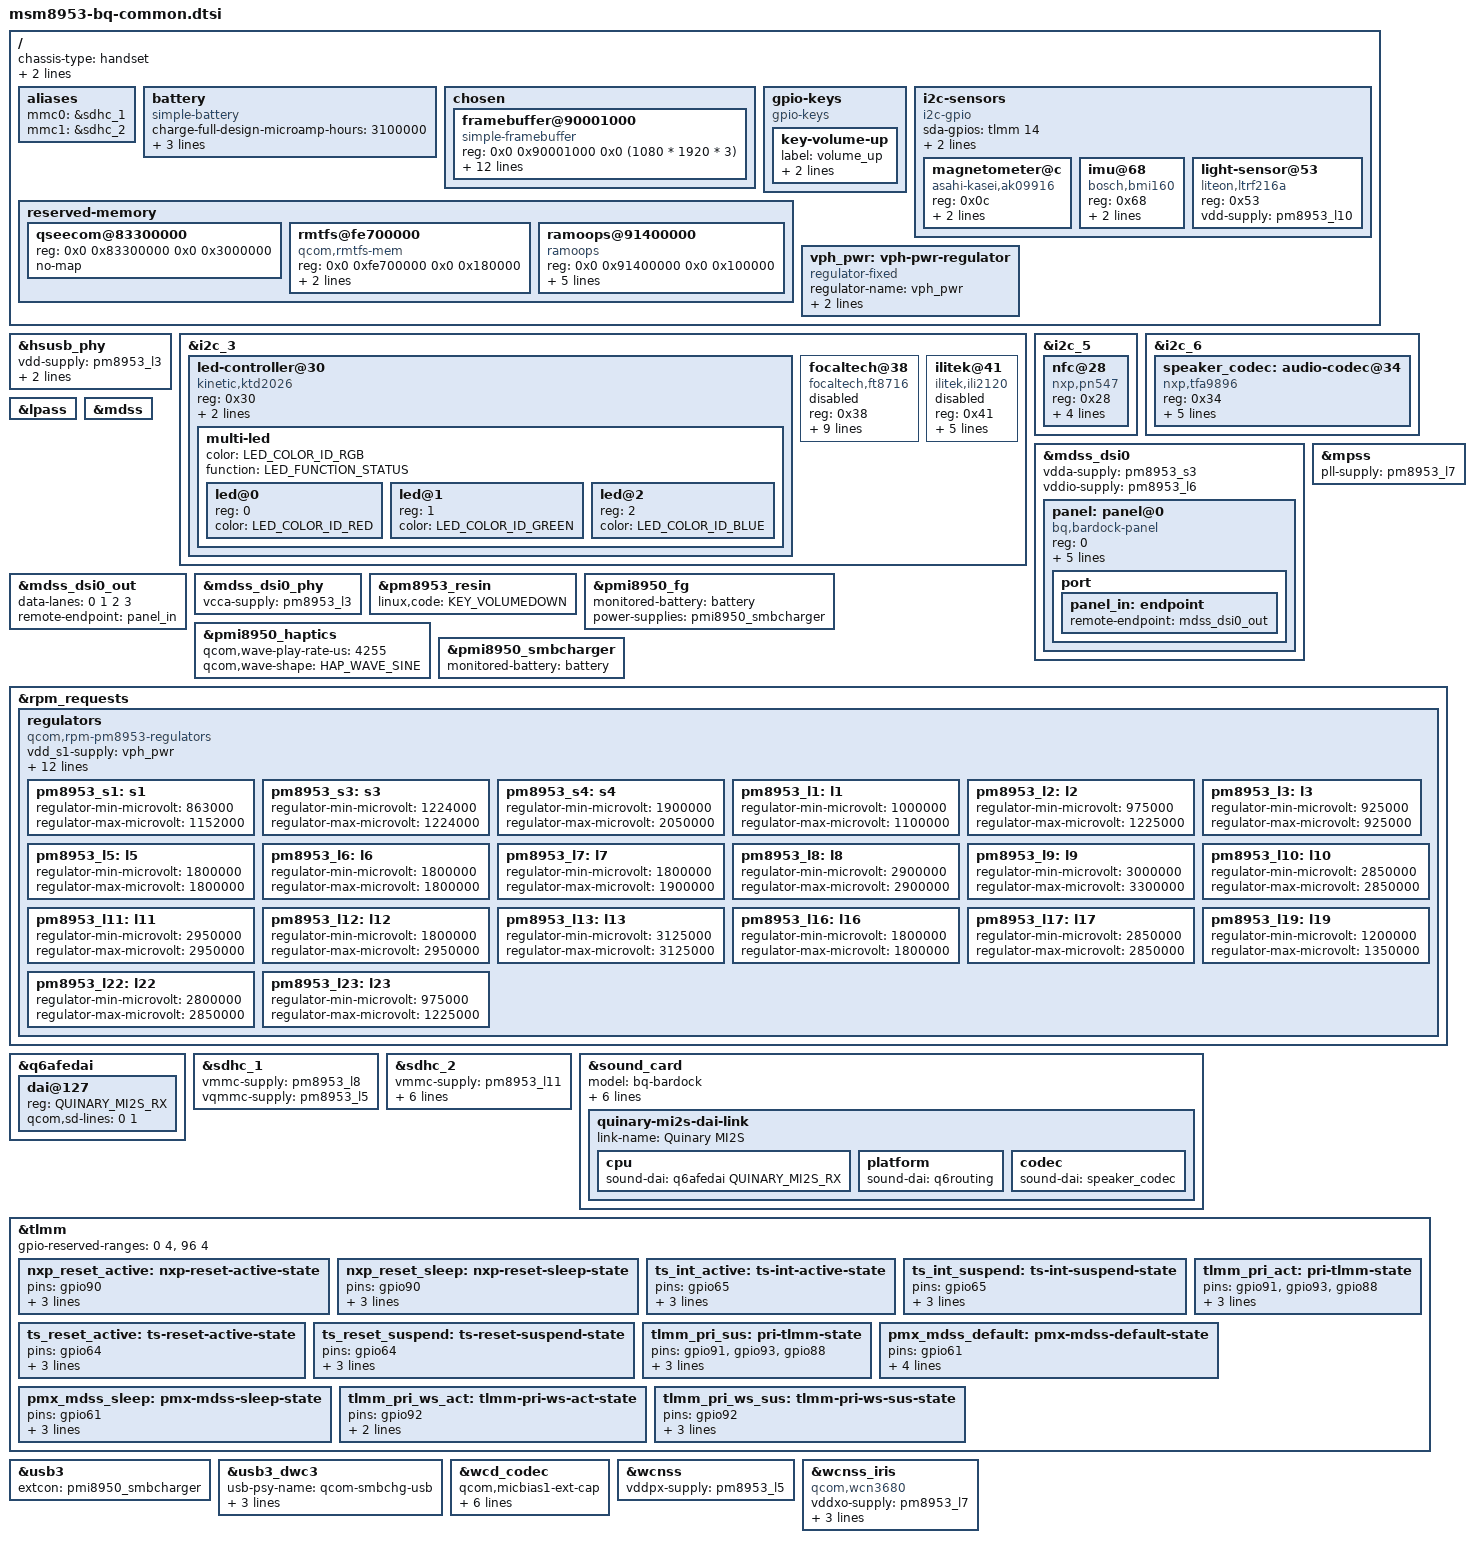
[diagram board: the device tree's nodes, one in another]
// SPDX-License-Identifier: BSD-3-Clause
/dts-v1/;

#include <dt-bindings/arm/qcom,ids.h>
#include <dt-bindings/leds/common.h>
#include "msm8953.dtsi"
#include "pm8953.dtsi"
#include "pmi8950.dtsi"

/delete-node/ &qseecom_mem;
/delete-node/ &rmtfs;

/ {
	chassis-type = "handset";
	qcom,msm-id = <QCOM_ID_MSM8953 0>;
	qcom,board-id = <QCOM_BOARD_ID(QRD, 32, 0) 0>;

	aliases {
		mmc0 = &sdhc_1;
		mmc1 = &sdhc_2;
	};

	battery: battery {
		compatible = "simple-battery";

		/* Either 3059mAh or 3133mAh depending on the battery used */
		charge-full-design-microamp-hours = <3100000>;
		constant-charge-current-max-microamp = <2100000>;
		voltage-min-design-microvolt = <3400000>;
		voltage-max-design-microvolt = <4400000>;
	};

	chosen {
		#address-cells = <2>;
		#size-cells = <2>;
		ranges;

		framebuffer@90001000 {
			compatible = "simple-framebuffer";
			reg = <0x0 0x90001000 0x0 (1080 * 1920 * 3)>;

			width = <1080>;
			height = <1920>;
			stride = <(1080 * 3)>;
			format = "r8g8b8";

			power-domains = <&gcc MDSS_GDSC>;

			clocks = <&gcc GCC_MDSS_AHB_CLK>,
				 <&gcc GCC_MDSS_AXI_CLK>,
				 <&gcc GCC_MDSS_VSYNC_CLK>,
				 <&gcc GCC_MDSS_MDP_CLK>,
				 <&gcc GCC_MDSS_BYTE0_CLK>,
				 <&gcc GCC_MDSS_PCLK0_CLK>,
				 <&gcc GCC_MDSS_ESC0_CLK>;
		};
	};

	gpio-keys {
		compatible = "gpio-keys";

		key-volume-up {
			label = "volume_up";
			linux,code = <KEY_VOLUMEUP>;
			gpios = <&tlmm 85 GPIO_ACTIVE_LOW>;
		};
	};

	/*
	 * We bitbang on &i2c_4 because BLSP is protected by TZ as sensors are
	 * normally proxied via ADSP firmware. GPIOs aren't protected.
	 */
	i2c-sensors {
		compatible = "i2c-gpio";
		sda-gpios = <&tlmm 14 (GPIO_ACTIVE_HIGH|GPIO_OPEN_DRAIN)>;
		scl-gpios = <&tlmm 15 (GPIO_ACTIVE_HIGH|GPIO_OPEN_DRAIN)>;
		i2c-gpio,delay-us = <2>; /* ~100 kHz */
		#address-cells = <1>;
		#size-cells = <0>;

		magnetometer@c {
			compatible = "asahi-kasei,ak09916";
			reg = <0x0c>;

			vdd-supply = <&pm8953_l10>;
			vid-supply = <&pm8953_l6>;
		};

		imu@68 {
			compatible = "bosch,bmi160";
			reg = <0x68>;

			vdd-supply = <&pm8953_l10>;
			vddio-supply = <&pm8953_l6>;
		};

		light-sensor@53 {
			/* it has ltr579 alps sensor */
			compatible = "liteon,ltrf216a";
			reg = <0x53>;
			vdd-supply = <&pm8953_l10>;
		};
	};

	reserved-memory {
		qseecom@83300000 {
			reg = <0x0 0x83300000 0x0 0x3000000>;
			no-map;
		};

		rmtfs@fe700000 {
			compatible = "qcom,rmtfs-mem";
			reg = <0x0 0xfe700000 0x0 0x180000>;
			no-map;

			qcom,client-id = <1>;
		};

		ramoops@91400000 {
			compatible = "ramoops";
			reg = <0x0 0x91400000 0x0 0x100000>;
			record-size = <0x10000>;
			console-size = <0x20000>;
			ftrace-size = <0x10000>;
			pmsg-size = <0x20000>;
			ecc-size = <0x10>;
		};
	};

	vph_pwr: vph-pwr-regulator {
		compatible = "regulator-fixed";
		regulator-name = "vph_pwr";
		regulator-always-on;
		regulator-boot-on;
	};
};

&hsusb_phy {
	vdd-supply = <&pm8953_l3>;
	vdda-pll-supply = <&pm8953_l7>;
	vdda-phy-dpdm-supply = <&pm8953_l13>;

	status = "okay";
};

&i2c_3 {
	status = "okay";

	led-controller@30 {
		compatible = "kinetic,ktd2026";
		reg = <0x30>;
		#address-cells = <1>;
		#size-cells = <0>;

		vin-supply = <&pm8953_l10>;
		vio-supply = <&pm8953_l6>;

		multi-led {
			color = <LED_COLOR_ID_RGB>;
			function = LED_FUNCTION_STATUS;

			#address-cells = <1>;
			#size-cells = <0>;

			led@0 {
				reg = <0>;
				color = <LED_COLOR_ID_RED>;
			};

			led@1 {
				reg = <1>;
				color = <LED_COLOR_ID_GREEN>;
			};

			led@2 {
				reg = <2>;
				color = <LED_COLOR_ID_BLUE>;
			};
		};
	};

	focaltech@38 {
		compatible = "focaltech,ft8716";
		reg = <0x38>;

		interrupt-parent = <&tlmm>;
		interrupts = <65 IRQ_TYPE_LEVEL_LOW>;

		pinctrl-names = "default", "sleep";
		pinctrl-0 = <&ts_reset_active &ts_int_active>;
		pinctrl-1 = <&ts_reset_suspend &ts_int_suspend>;

		reset-gpios = <&tlmm 64 GPIO_ACTIVE_LOW>;

		iovcc-supply = <&pm8953_l6>;
		vcc-supply = <&pm8953_l10>;

		touchscreen-size-x = <1080>;
		touchscreen-size-y = <1920>;

		status = "disabled";
	};

	ilitek@41 {
		compatible = "ilitek,ili2120";
		reg = <0x41>;

		interrupt-parent = <&tlmm>;
		interrupts = <65 IRQ_TYPE_LEVEL_LOW>;

		reset-gpios = <&tlmm 64 GPIO_ACTIVE_LOW>;

		touchscreen-size-x = <1080>;
		touchscreen-size-y = <1920>;

		status = "disabled";
	};
};

&i2c_5 {
	status = "okay";

	nfc@28 {
		compatible = "nxp,pn547", "nxp,nxp-nci-i2c";
		reg = <0x28>;

		interrupt-parent = <&tlmm>;
		interrupts = <17 IRQ_TYPE_EDGE_RISING>;

		enable-gpios = <&tlmm 16 GPIO_ACTIVE_HIGH>;
		firmware-gpios = <&tlmm 62 GPIO_ACTIVE_HIGH>;
	};
};

&i2c_6 {
	status = "okay";

	speaker_codec: audio-codec@34 {
		compatible = "nxp,tfa9896";
		reg = <0x34>;

		reset-gpio = <&tlmm 89 GPIO_ACTIVE_HIGH>;
		irq-gpio = <&tlmm 90 GPIO_ACTIVE_HIGH>;

		pinctrl-names = "default", "sleep";
		pinctrl-0 = <&nxp_reset_active>;
		pinctrl-1 = <&nxp_reset_sleep>;

		sound-name-prefix = "Speaker";
		#sound-dai-cells = <0>;
	};
};

&lpass {
	status = "okay";
};

&mdss {
	status = "okay";
};

&mdss_dsi0 {
	status = "okay";

	vdda-supply = <&pm8953_s3>;
	vddio-supply = <&pm8953_l6>;

	panel: panel@0 {
		compatible = "bq,bardock-panel";
		reg = <0>;

		pinctrl-names = "default", "sleep";
		pinctrl-0 = <&pmx_mdss_default &mdss_te_default>;
		pinctrl-1 = <&pmx_mdss_sleep &mdss_te_default>;

		reset-gpios = <&tlmm 61 GPIO_ACTIVE_LOW>;

		vsp-supply = <&lab_vreg>;
		vsn-supply = <&ibb_vreg>;

		port {
			panel_in: endpoint {
				remote-endpoint = <&mdss_dsi0_out>;
			};
		};
	};
};

&mdss_dsi0_out {
	data-lanes = <0 1 2 3>;
	remote-endpoint = <&panel_in>;
};

&mdss_dsi0_phy {
	vcca-supply = <&pm8953_l3>;

	status = "okay";
};

&mpss {
	pll-supply = <&pm8953_l7>;

	status = "okay";
};

&pm8953_resin {
	linux,code = <KEY_VOLUMEDOWN>;
	status = "okay";
};

&pmi8950_fg {
	monitored-battery = <&battery>;
	power-supplies = <&pmi8950_smbcharger>;
	status = "okay";
};

&pmi8950_haptics {
	qcom,wave-play-rate-us = <4255>;
	qcom,wave-shape = <HAP_WAVE_SINE>;
	status = "okay";
};

&pmi8950_smbcharger {
	monitored-battery = <&battery>;
	status = "okay";
};

&rpm_requests {
	regulators {
		compatible = "qcom,rpm-pm8953-regulators";

		vdd_s1-supply = <&vph_pwr>;
		vdd_s2-supply = <&vph_pwr>;
		vdd_s3-supply = <&vph_pwr>;
		vdd_s4-supply = <&vph_pwr>;
		vdd_s5-supply = <&vph_pwr>;
		vdd_s6-supply = <&vph_pwr>;
		vdd_s7-supply = <&vph_pwr>;
		vdd_l1-supply = <&pm8953_s3>;
		vdd_l2_l3-supply = <&pm8953_s3>;
		vdd_l4_l5_l6_l7_l16_l19-supply = <&pm8953_s4>;
		vdd_l8_l11_l12_l13_l14_l15-supply = <&vph_pwr>;
		vdd_l9_l10_l17_l18_l22-supply = <&vph_pwr>;
		vdd_l23-supply = <&pm8953_s3>;

		pm8953_s1: s1 {
			regulator-min-microvolt = <863000>;
			regulator-max-microvolt = <1152000>;
		};

		pm8953_s3: s3 {
			regulator-min-microvolt = <1224000>;
			regulator-max-microvolt = <1224000>;
		};

		pm8953_s4: s4 {
			regulator-min-microvolt = <1900000>;
			regulator-max-microvolt = <2050000>;
		};

		pm8953_l1: l1 {
			regulator-min-microvolt = <1000000>;
			regulator-max-microvolt = <1100000>;
		};

		pm8953_l2: l2 {
			regulator-min-microvolt = <975000>;
			regulator-max-microvolt = <1225000>;
		};

		pm8953_l3: l3 {
			regulator-min-microvolt = <925000>;
			regulator-max-microvolt = <925000>;
		};

		pm8953_l5: l5 {
			regulator-min-microvolt = <1800000>;
			regulator-max-microvolt = <1800000>;
		};

		pm8953_l6: l6 {
			regulator-min-microvolt = <1800000>;
			regulator-max-microvolt = <1800000>;
		};

		pm8953_l7: l7 {
			regulator-min-microvolt = <1800000>;
			regulator-max-microvolt = <1900000>;
		};

		pm8953_l8: l8 {
			regulator-min-microvolt = <2900000>;
			regulator-max-microvolt = <2900000>;
		};

		pm8953_l9: l9 {
			regulator-min-microvolt = <3000000>;
			regulator-max-microvolt = <3300000>;
		};

		pm8953_l10: l10 {
			regulator-min-microvolt = <2850000>;
			regulator-max-microvolt = <2850000>;
		};

		pm8953_l11: l11 {
			regulator-min-microvolt = <2950000>;
			regulator-max-microvolt = <2950000>;
		};

		pm8953_l12: l12 {
			regulator-min-microvolt = <1800000>;
			regulator-max-microvolt = <2950000>;
		};

		pm8953_l13: l13 {
			regulator-min-microvolt = <3125000>;
			regulator-max-microvolt = <3125000>;
		};

		pm8953_l16: l16 {
			regulator-min-microvolt = <1800000>;
			regulator-max-microvolt = <1800000>;
		};

		pm8953_l17: l17 {
			regulator-min-microvolt = <2850000>;
			regulator-max-microvolt = <2850000>;
		};

		pm8953_l19: l19 {
			regulator-min-microvolt = <1200000>;
			regulator-max-microvolt = <1350000>;
		};

		pm8953_l22: l22 {
			regulator-min-microvolt = <2800000>;
			regulator-max-microvolt = <2850000>;
		};

		pm8953_l23: l23 {
			regulator-min-microvolt = <975000>;
			regulator-max-microvolt = <1225000>;
		};
	};
};

&q6afedai {
	dai@127 {
		reg = <QUINARY_MI2S_RX>;
		qcom,sd-lines = <0 1>;
	};
};

&sdhc_1 {
	vmmc-supply = <&pm8953_l8>;
	vqmmc-supply = <&pm8953_l5>;

	status = "okay";
};

&sdhc_2 {
	vmmc-supply = <&pm8953_l11>;
	vqmmc-supply = <&pm8953_l12>;

	pinctrl-names = "default", "sleep";
	pinctrl-0 = <&sdc2_clk_on &sdc2_cmd_on &sdc2_data_on &sdc2_cd_on>;
	pinctrl-1 = <&sdc2_clk_off &sdc2_cmd_off &sdc2_data_off &sdc2_cd_off>;

	cd-gpios = <&tlmm 133 GPIO_ACTIVE_HIGH>;

	status = "okay";
};

&sound_card {
	model = "bq-bardock";

	pinctrl-names = "default", "sleep";
	pinctrl-0 = <&cdc_pdm_lines_act
		&cdc_pdm_lines_2_act
		&cdc_pdm_comp_lines_act
		&tlmm_pri_act
		&tlmm_pri_ws_act>;
	pinctrl-1 = <&cdc_pdm_lines_sus
		&cdc_pdm_lines_2_sus
		&cdc_pdm_comp_lines_sus
		&tlmm_pri_sus
		&tlmm_pri_ws_sus>;

	status = "okay";

	quinary-mi2s-dai-link {
		link-name = "Quinary MI2S";

		cpu {
			sound-dai = <&q6afedai QUINARY_MI2S_RX>;
		};

		platform {
			sound-dai = <&q6routing>;
		};

		codec {
			sound-dai = <&speaker_codec>;
		};
	};
};

&tlmm {
	gpio-reserved-ranges = <0 4>, <96 4>;

	nxp_reset_active: nxp-reset-active-state {
		pins = "gpio90";
		function = "gpio";
		drive-strength = <6>;
		bias-pull-up;
	};

	nxp_reset_sleep: nxp-reset-sleep-state {
		pins = "gpio90";
		function = "gpio";
		drive-strength = <2>;
		bias-disable;
	};

	ts_int_active: ts-int-active-state {
		pins = "gpio65";
		function = "gpio";
		drive-strength = <8>;
		bias-pull-up;
	};

	ts_int_suspend: ts-int-suspend-state {
		pins = "gpio65";
		function = "gpio";
		drive-strength = <2>;
		bias-pull-down;
	};

	ts_reset_active: ts-reset-active-state {
		pins = "gpio64";
		function = "gpio";
		drive-strength = <8>;
		bias-pull-up;
	};

	ts_reset_suspend: ts-reset-suspend-state {
		pins = "gpio64";
		function = "gpio";
		drive-strength = <2>;
		bias-pull-down;
	};

	tlmm_pri_act: pri-tlmm-state {
		pins = "gpio91", "gpio93", "gpio88";
		function = "pri_mi2s";
		drive-strength = <8>;
		bias-disable;
	};

	tlmm_pri_sus: pri-tlmm-state {
		pins = "gpio91", "gpio93", "gpio88";
		function = "pri_mi2s";
		drive-strength = <2>;
		bias-pull-down;
	};

	pmx_mdss_default: pmx-mdss-default-state {
		pins = "gpio61";
		function = "gpio";
		drive-strength = <8>;
		bias-disable;
		output-high;
	};

	pmx_mdss_sleep: pmx-mdss-sleep-state {
		pins = "gpio61";
		function = "gpio";
		drive-strength = <2>;
		bias-pull-down;
	};

	tlmm_pri_ws_act: tlmm-pri-ws-act-state {
		pins = "gpio92";
		function = "pri_mi2s_ws";
		drive-strength = <8>;
	};

	tlmm_pri_ws_sus: tlmm-pri-ws-sus-state {
		pins = "gpio92";
		function = "pri_mi2s_ws";
		drive-strength = <2>;
		bias-pull-down;
	};
};

&usb3 {
	extcon = <&pmi8950_smbcharger>;
	status = "okay";
};

&usb3_dwc3 {
	usb-psy-name = "qcom-smbchg-usb";
	extcon = <&pmi8950_smbcharger>;
	vbus-supply = <&otg_vbus>;
	dr_mode = "otg";
};

&wcd_codec {
	status = "okay";

	qcom,micbias1-ext-cap;
	qcom,hphl-jack-type-normally-open;
	qcom,mbhc-vthreshold-low = <75 300 500 700 700>;
	qcom,mbhc-vthreshold-high = <75 300 500 700 700>;

	vdd-cdc-io-supply = <&pm8953_l5>;
	vdd-cdc-tx-rx-cx-supply = <&pm8953_s4>;
	vdd-micbias-supply = <&pm8953_l13>;
};

&wcnss {
	vddpx-supply = <&pm8953_l5>;
	status = "okay";
};

&wcnss_iris {
	compatible = "qcom,wcn3680";

	vddxo-supply = <&pm8953_l7>;
	vddrfa-supply = <&pm8953_l19>;
	vddpa-supply = <&pm8953_l9>;
	vdddig-supply = <&pm8953_l5>;

	status = "okay";
};
